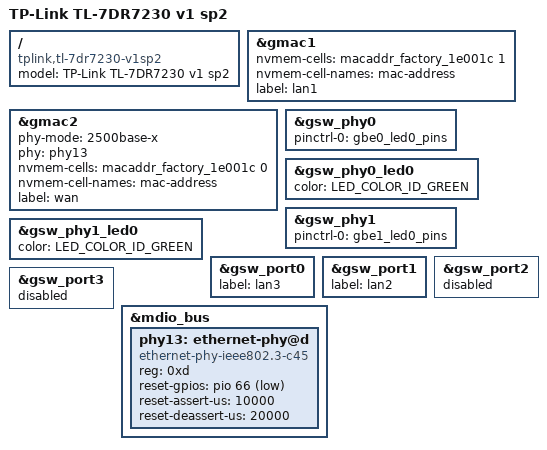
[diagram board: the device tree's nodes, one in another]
// SPDX-License-Identifier: GPL-2.0-or-later OR MIT
/*
 * Copyright (C) 2025 Tianling Shen <cnsztl@immortalwrt.org>
 */

/dts-v1/;
#include "mt7988d-tplink-tl-7dr-common.dtsi"

/ {
	model = "TP-Link TL-7DR7230 v1 sp2";
	compatible = "tplink,tl-7dr7230-v1sp2", "mediatek,mt7988d";
};

&gmac1 {
	nvmem-cells = <&macaddr_factory_1e001c 1>;
	nvmem-cell-names = "mac-address";
	label = "lan1";
};

&gmac2 {
	phy-mode = "2500base-x";
	phy = <&phy13>;
	nvmem-cells = <&macaddr_factory_1e001c 0>;
	nvmem-cell-names = "mac-address";
	label = "wan";
	status = "okay";
};

&gsw_phy0 {
	pinctrl-names = "gbe-led";
	pinctrl-0 = <&gbe0_led0_pins>;
};

&gsw_phy0_led0 {
	color = <LED_COLOR_ID_GREEN>;
	status = "okay";
};

&gsw_phy1 {
	pinctrl-names = "gbe-led";
	pinctrl-0 = <&gbe1_led0_pins>;
};

&gsw_phy1_led0 {
	color = <LED_COLOR_ID_GREEN>;
	status = "okay";
};

&gsw_port0 {
	label = "lan3";
};

&gsw_port1 {
	label = "lan2";
};

&gsw_port2 {
	status = "disabled";
};

&gsw_port3 {
	status = "disabled";
};

&mdio_bus {
	phy13: ethernet-phy@d {
		reg = <0xd>;
		compatible = "ethernet-phy-ieee802.3-c45";
		reset-gpios = <&pio 66 GPIO_ACTIVE_LOW>;
		reset-assert-us = <10000>;
		reset-deassert-us = <20000>;
	};
};
